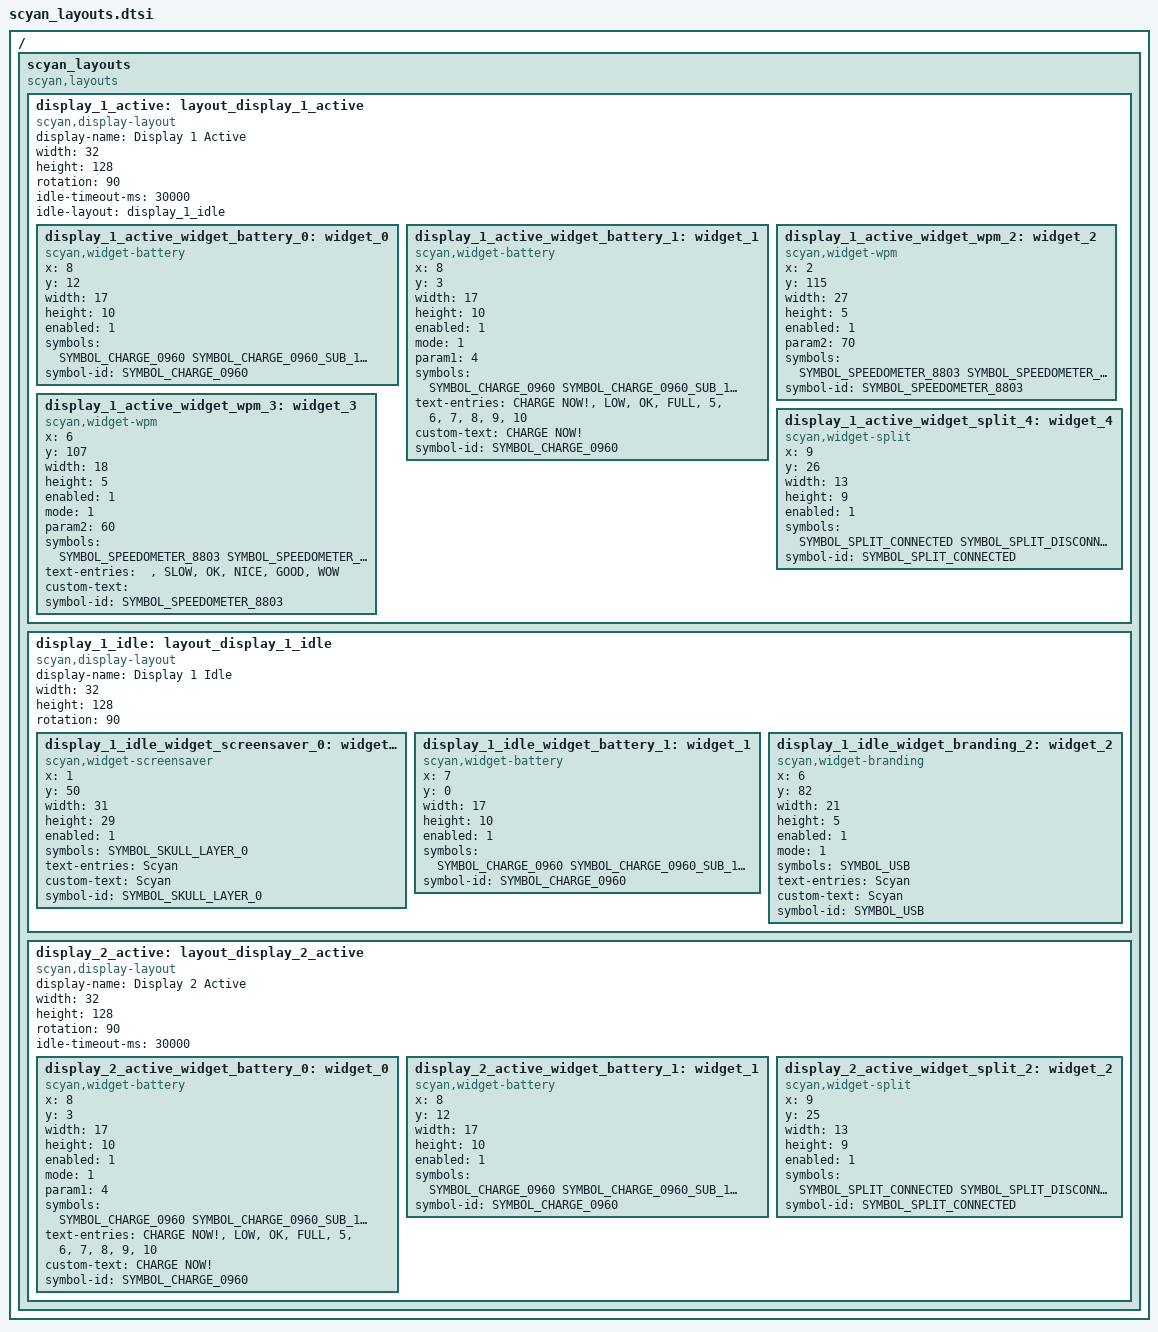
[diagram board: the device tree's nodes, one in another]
/*
 * Generated by Scyan ZMK Studio
 * Do NOT edit manually.
 */

#include "scyan_symbols.dtsi"

/ {
    scyan_layouts {
        compatible = "scyan,layouts";

        display_1_active: layout_display_1_active {
            compatible = "scyan,display-layout";
            display-name = "Display 1 Active";
            width = <32>;
            height = <128>;
            rotation = <90>;
            idle-timeout-ms = <30000>;
            idle-layout = <&display_1_idle>;

            display_1_active_widget_battery_0: widget_0 {
                compatible = "scyan,widget-battery";
                x = <8>;
                y = <12>;
                width = <17>;
                height = <10>;
                enabled = <1>;
                symbols = <SYMBOL_CHARGE_0960 SYMBOL_CHARGE_0960_SUB_1 SYMBOL_CHARGE_0960_SUB_2 SYMBOL_CHARGE_0960_SUB_3 SYMBOL_CHARGE_0960_SUB_4 SYMBOL_CHARGE_0960_SUB_5 SYMBOL_CHARGE_0960_SUB_6 SYMBOL_CHARGE_0960_SUB_7 SYMBOL_CHARGE_0960_SUB_8 SYMBOL_CHARGE_0960_SUB_9 SYMBOL_CHARGE_0960_SUB_10 SYMBOL_CHARGE_0960_SUB_11 SYMBOL_CHARGE_0960_SUB_12 SYMBOL_BATTERY_FRAME>;
                symbol-id = <SYMBOL_CHARGE_0960>;
            };
            display_1_active_widget_battery_1: widget_1 {
                compatible = "scyan,widget-battery";
                x = <8>;
                y = <3>;
                width = <17>;
                height = <10>;
                enabled = <1>;
                mode = <1>;
                param1 = <4>;
                symbols = <SYMBOL_CHARGE_0960 SYMBOL_CHARGE_0960_SUB_1 SYMBOL_CHARGE_0960_SUB_2 SYMBOL_CHARGE_0960_SUB_3 SYMBOL_CHARGE_0960_SUB_4 SYMBOL_CHARGE_0960_SUB_5 SYMBOL_CHARGE_0960_SUB_6 SYMBOL_CHARGE_0960_SUB_7 SYMBOL_CHARGE_0960_SUB_8 SYMBOL_CHARGE_0960_SUB_9 SYMBOL_CHARGE_0960_SUB_10 SYMBOL_CHARGE_0960_SUB_11 SYMBOL_CHARGE_0960_SUB_12 SYMBOL_BATTERY_FRAME SYMBOL_CHARGESLIM_5317 SYMBOL_CHARGESLIM_5317_SUB_1>;
                text-entries = "CHARGE NOW!", "LOW", "OK", "FULL", "5", "6", "7", "8", "9", "10";
                custom-text = "CHARGE NOW!";
                symbol-id = <SYMBOL_CHARGE_0960>;
            };
            display_1_active_widget_wpm_2: widget_2 {
                compatible = "scyan,widget-wpm";
                x = <2>;
                y = <115>;
                width = <27>;
                height = <5>;
                enabled = <1>;
                param2 = <70>;
                symbols = <SYMBOL_SPEEDOMETER_8803 SYMBOL_SPEEDOMETER_8803_SUB_1 SYMBOL_SPEEDOMETER_8803_SUB_2 SYMBOL_SPEEDOMETER_8803_SUB_3 SYMBOL_SPEEDOMETER_8803_SUB_4 SYMBOL_SPEEDOMETER_8803_SUB_5 SYMBOL_SPEEDOMETER_8803_SUB_6 SYMBOL_SPEEDOMETER_8803_SUB_7>;
                symbol-id = <SYMBOL_SPEEDOMETER_8803>;
            };
            display_1_active_widget_wpm_3: widget_3 {
                compatible = "scyan,widget-wpm";
                x = <6>;
                y = <107>;
                width = <18>;
                height = <5>;
                enabled = <1>;
                mode = <1>;
                param2 = <60>;
                symbols = <SYMBOL_SPEEDOMETER_8803 SYMBOL_SPEEDOMETER_8803_SUB_1 SYMBOL_SPEEDOMETER_8803_SUB_2 SYMBOL_SPEEDOMETER_8803_SUB_3 SYMBOL_SPEEDOMETER_8803_SUB_4 SYMBOL_SPEEDOMETER_8803_SUB_5 SYMBOL_SPEEDOMETER_8803_SUB_6 SYMBOL_SPEEDOMETER_8803_SUB_7 SYMBOL_ARROW_UP SYMBOL_ARROW_DOWN SYMBOL_ARROW_LEFT SYMBOL_ARROW_RIGHT>;
                text-entries = " ", "SLOW", "OK", "NICE", "GOOD", "WOW";
                custom-text = " ";
                symbol-id = <SYMBOL_SPEEDOMETER_8803>;
            };
            display_1_active_widget_split_4: widget_4 {
                compatible = "scyan,widget-split";
                x = <9>;
                y = <26>;
                width = <13>;
                height = <9>;
                enabled = <1>;
                symbols = <SYMBOL_SPLIT_CONNECTED SYMBOL_SPLIT_DISCONNECTED>;
                symbol-id = <SYMBOL_SPLIT_CONNECTED>;
            };
        };

        display_1_idle: layout_display_1_idle {
            compatible = "scyan,display-layout";
            display-name = "Display 1 Idle";
            width = <32>;
            height = <128>;
            rotation = <90>;

            display_1_idle_widget_screensaver_0: widget_0 {
                compatible = "scyan,widget-screensaver";
                x = <1>;
                y = <50>;
                width = <31>;
                height = <29>;
                enabled = <1>;
                symbols = <SYMBOL_SKULL_LAYER_0>;
                text-entries = "Scyan";
                custom-text = "Scyan";
                symbol-id = <SYMBOL_SKULL_LAYER_0>;
            };
            display_1_idle_widget_battery_1: widget_1 {
                compatible = "scyan,widget-battery";
                x = <7>;
                y = <0>;
                width = <17>;
                height = <10>;
                enabled = <1>;
                symbols = <SYMBOL_CHARGE_0960 SYMBOL_CHARGE_0960_SUB_1 SYMBOL_CHARGE_0960_SUB_2 SYMBOL_CHARGE_0960_SUB_3 SYMBOL_CHARGE_0960_SUB_4 SYMBOL_CHARGE_0960_SUB_5 SYMBOL_CHARGE_0960_SUB_6 SYMBOL_CHARGE_0960_SUB_7 SYMBOL_CHARGE_0960_SUB_8 SYMBOL_CHARGE_0960_SUB_9 SYMBOL_CHARGE_0960_SUB_10 SYMBOL_CHARGE_0960_SUB_11 SYMBOL_CHARGE_0960_SUB_12 SYMBOL_BATTERY_FRAME>;
                symbol-id = <SYMBOL_CHARGE_0960>;
            };
            display_1_idle_widget_branding_2: widget_2 {
                compatible = "scyan,widget-branding";
                x = <6>;
                y = <82>;
                width = <21>;
                height = <5>;
                enabled = <1>;
                mode = <1>;
                symbols = <SYMBOL_USB>;
                text-entries = "Scyan";
                custom-text = "Scyan";
                symbol-id = <SYMBOL_USB>;
            };
        };

        display_2_active: layout_display_2_active {
            compatible = "scyan,display-layout";
            display-name = "Display 2 Active";
            width = <32>;
            height = <128>;
            rotation = <90>;
            idle-timeout-ms = <30000>;

            display_2_active_widget_battery_0: widget_0 {
                compatible = "scyan,widget-battery";
                x = <8>;
                y = <3>;
                width = <17>;
                height = <10>;
                enabled = <1>;
                mode = <1>;
                param1 = <4>;
                symbols = <SYMBOL_CHARGE_0960 SYMBOL_CHARGE_0960_SUB_1 SYMBOL_CHARGE_0960_SUB_2 SYMBOL_CHARGE_0960_SUB_3 SYMBOL_CHARGE_0960_SUB_4 SYMBOL_CHARGE_0960_SUB_5 SYMBOL_CHARGE_0960_SUB_6 SYMBOL_CHARGE_0960_SUB_7 SYMBOL_CHARGE_0960_SUB_8 SYMBOL_CHARGE_0960_SUB_9 SYMBOL_CHARGE_0960_SUB_10 SYMBOL_CHARGE_0960_SUB_11 SYMBOL_CHARGE_0960_SUB_12 SYMBOL_BATTERY_FRAME SYMBOL_CHARGESLIM_5317 SYMBOL_CHARGESLIM_5317_SUB_1>;
                text-entries = "CHARGE NOW!", "LOW", "OK", "FULL", "5", "6", "7", "8", "9", "10";
                custom-text = "CHARGE NOW!";
                symbol-id = <SYMBOL_CHARGE_0960>;
            };
            display_2_active_widget_battery_1: widget_1 {
                compatible = "scyan,widget-battery";
                x = <8>;
                y = <12>;
                width = <17>;
                height = <10>;
                enabled = <1>;
                symbols = <SYMBOL_CHARGE_0960 SYMBOL_CHARGE_0960_SUB_1 SYMBOL_CHARGE_0960_SUB_2 SYMBOL_CHARGE_0960_SUB_3 SYMBOL_CHARGE_0960_SUB_4 SYMBOL_CHARGE_0960_SUB_5 SYMBOL_CHARGE_0960_SUB_6 SYMBOL_CHARGE_0960_SUB_7 SYMBOL_CHARGE_0960_SUB_8 SYMBOL_CHARGE_0960_SUB_9 SYMBOL_CHARGE_0960_SUB_10 SYMBOL_CHARGE_0960_SUB_11 SYMBOL_CHARGE_0960_SUB_12 SYMBOL_BATTERY_FRAME>;
                symbol-id = <SYMBOL_CHARGE_0960>;
            };
            display_2_active_widget_split_2: widget_2 {
                compatible = "scyan,widget-split";
                x = <9>;
                y = <25>;
                width = <13>;
                height = <9>;
                enabled = <1>;
                symbols = <SYMBOL_SPLIT_CONNECTED SYMBOL_SPLIT_DISCONNECTED>;
                symbol-id = <SYMBOL_SPLIT_CONNECTED>;
            };
        };
    };
};
